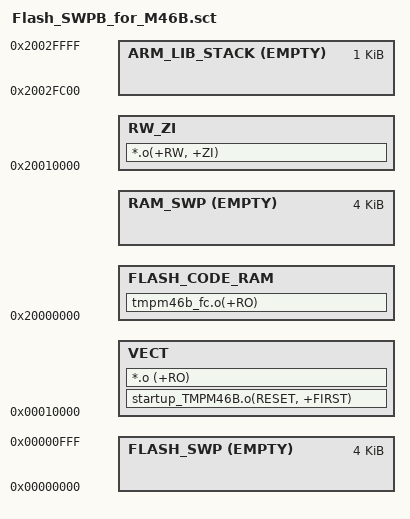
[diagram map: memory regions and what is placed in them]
;;  TMPM46B scatter file

;;  Vector table starts at 0
;;    Initial SP == |Image$$ARM_LIB_STACK$$ZI$$Limit| (for two region model)
;;               or |Image$$ARM_LIB_STACKHEAP$$ZI$$Limit| (for one region model)
;;    Initial PC == &__main (with LSB set to indicate Thumb)
;;    These two values are provided by the library
;;    Other vectors must be provided by the user
;;  Code starts after the last possible vector
;;  Data starts at 0x20000000
;;    Heap is positioned by ARM_LIB_HEAB (this is the heap managed by the ARM libraries)
;;    Stack is positioned by ARM_LIB_STACK (library will use this to set SP - see above)

;; Compatible with ISSM model

LOAD_ROM 0x00010000
{ 
;;ROM_region
    VECT             0x00010000 	   
	{ 
	 startup_TMPM46B.o(RESET, +FIRST)  
     *.o (+RO) 
    }	 
        
    FLASH_SWP     0x00000  EMPTY 0x1000 {}

;;RAM_region

    FLASH_CODE_RAM   0x20000000
    {
     tmpm46b_fc.o(+RO)     
    }  
    
    RAM_SWP   +0  EMPTY 0x1000 {} 
    
    RW_ZI   0x20010000
    {
       *.o(+RW, +ZI)	   
    }
	  
    ARM_LIB_STACK   0x20030000 EMPTY -0x400 {}
	  
}
